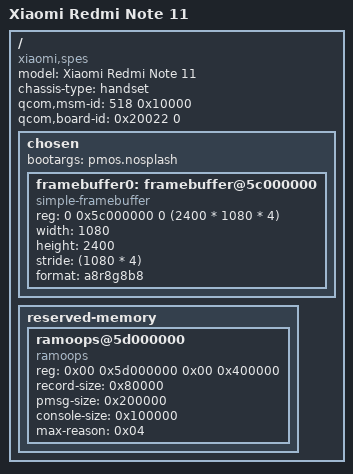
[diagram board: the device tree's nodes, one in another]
// SPDX-License-Identifier: BSD-3-Clause
/*
 * Copyright (c) 2026, Rayan Marzouk <rayanmarzouk743@gmail.com>
 */

/dts-v1/;
#include "sm6225.dtsi"

/ {
	model = "Xiaomi Redmi Note 11";
	compatible = "xiaomi,spes", "qcom,sm6225";
	chassis-type = "handset";

	/* required for xbl */
	qcom,msm-id = <518 0x10000>;
	qcom,board-id = <0x20022 0>;


	chosen {
		#address-cells = <2>;
		#size-cells = <2>;
		ranges;

		bootargs = "pmos.nosplash";

		framebuffer0: framebuffer@5c000000 {
			compatible = "simple-framebuffer";
			reg = <0 0x5c000000 0 (2400 * 1080 * 4)>;
			width = <1080>;
			height = <2400>;
			stride = <(1080 * 4)>;
			format = "a8r8g8b8";
		};
	};

	reserved-memory {
		#adress-cells = <2>;
		#size-cells = <2>;
		ranges;

		ramoops@5d000000 {
			compatible = "ramoops";
			reg = <0x00 0x5d000000 0x00 0x400000>;
			record-size = <0x80000>;
			pmsg-size = <0x200000>;
			console-size = <0x100000>;
			max-reason = <0x04>;
		};
	};
};
